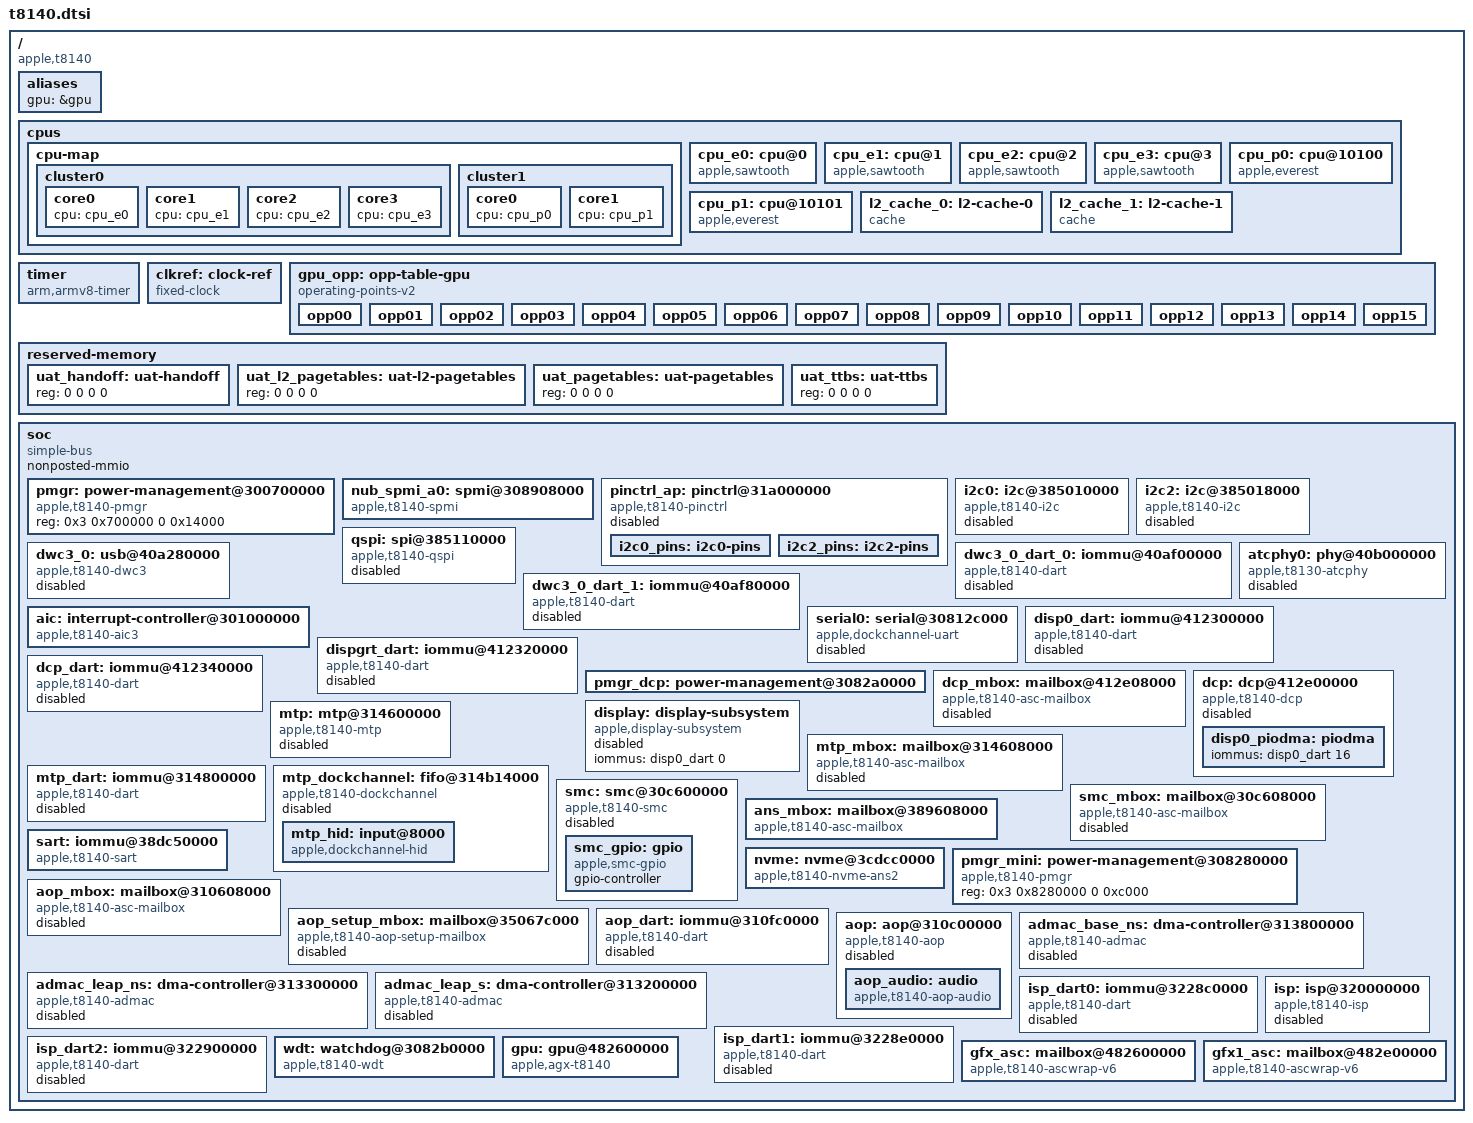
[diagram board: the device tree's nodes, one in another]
// SPDX-License-Identifier: GPL-2.0+ OR MIT
/*
 * Apple T8140 "A18 Pro" SoC
 *
 * Copyright The Asahi Linux Contributors
 */

#include <dt-bindings/interrupt-controller/apple-aic.h>
#include <dt-bindings/interrupt-controller/irq.h>
#include <dt-bindings/gpio/gpio.h>
#include <dt-bindings/pinctrl/apple.h>
#include <dt-bindings/phy/phy.h>
#include <dt-bindings/spmi/spmi.h>

/ {
	compatible = "apple,t8140", "apple,arm-platform";

	#address-cells = <2>;
	#size-cells = <2>;

	aliases {
		gpu = &gpu;
	};

	cpus {
		#address-cells = <2>;
		#size-cells = <0>;

		cpu-map {
			cluster0 {
				core0 {
					cpu = <&cpu_e0>;
				};
				core1 {
					cpu = <&cpu_e1>;
				};
				core2 {
					cpu = <&cpu_e2>;
				};
				core3 {
					cpu = <&cpu_e3>;
				};
			};

			cluster1 {
				core0 {
					cpu = <&cpu_p0>;
				};
				core1 {
					cpu = <&cpu_p1>;
				};
			};
		};

		cpu_e0: cpu@0 {
			compatible = "apple,sawtooth";
			device_type = "cpu";
			reg = <0x0 0x0>;
			enable-method = "spin-table";
			cpu-release-addr = <0 0>;
			next-level-cache = <&l2_cache_0>;
		};

		cpu_e1: cpu@1 {
			compatible = "apple,sawtooth";
			device_type = "cpu";
			reg = <0x0 0x1>;
			enable-method = "spin-table";
			cpu-release-addr = <0 0>;
			next-level-cache = <&l2_cache_0>;
		};


		cpu_e2: cpu@2 {
			compatible = "apple,sawtooth";
			device_type = "cpu";
			reg = <0x0 0x2>;
			enable-method = "spin-table";
			cpu-release-addr = <0 0>;
			next-level-cache = <&l2_cache_0>;
		};

		cpu_e3: cpu@3 {
			compatible = "apple,sawtooth";
			device_type = "cpu";
			reg = <0x0 0x3>;
			enable-method = "spin-table";
			cpu-release-addr = <0 0>;
			next-level-cache = <&l2_cache_0>;
		};

		cpu_p0: cpu@10100 {
			compatible = "apple,everest";
			device_type = "cpu";
			reg = <0x0 0x10100>;
			enable-method = "spin-table";
			cpu-release-addr = <0 0>;
			next-level-cache = <&l2_cache_1>;
		};

		cpu_p1: cpu@10101 {
			compatible = "apple,everest";
			device_type = "cpu";
			reg = <0x0 0x10101>;
			enable-method = "spin-table";
			cpu-release-addr = <0 0>;
			next-level-cache = <&l2_cache_1>;
		};

		l2_cache_0: l2-cache-0 {
			compatible = "cache";
			cache-level = <2>;
			cache-unified;
			cache-size = <0x400000>;
		};

		l2_cache_1: l2-cache-1 {
			compatible = "cache";
			cache-level = <2>;
			cache-unified;
			cache-size = <0x1000000>;
		};
	};

	timer {
		compatible = "arm,armv8-timer";
		interrupt-parent = <&aic>;
		interrupt-names = "phys", "virt", "hyp-phys", "hyp-virt";
		interrupts = <AIC_FIQ AIC_TMR_GUEST_PHYS IRQ_TYPE_LEVEL_HIGH>,
		             <AIC_FIQ AIC_TMR_GUEST_VIRT IRQ_TYPE_LEVEL_HIGH>,
		             <AIC_FIQ AIC_TMR_HV_PHYS IRQ_TYPE_LEVEL_HIGH>,
		             <AIC_FIQ AIC_TMR_HV_VIRT IRQ_TYPE_LEVEL_HIGH>;
	};

	clkref: clock-ref {
		compatible = "fixed-clock";
		#clock-cells = <0>;
		clock-frequency = <24000000>;
		clock-output-names = "clkref";
	};

	gpu_opp: opp-table-gpu {
		compatible = "operating-points-v2";

		/*
		 * NOTE: This ladder is the live J700 (Mac17,5) ADT
		 * perf-states table, kept in ADT order (the two interleaved
		 * rails make it non-monotonic); the bootloader rewrites it
		 * from each device's ADT.  opp-microwatt is deliberately
		 * absent: no G17P power model is grounded yet, and m1n1
		 * fails closed rather than inventing per-state power.
		 */
		opp00 {
			opp-hz = /bits/ 64 <0>;
			opp-microvolt = <125000>;
		};
		opp01 {
			opp-hz = /bits/ 64 <338000000>;
			opp-microvolt = <605000>;
		};
		opp02 {
			opp-hz = /bits/ 64 <492000000>;
			opp-microvolt = <630000>;
		};
		opp03 {
			opp-hz = /bits/ 64 <618000000>;
			opp-microvolt = <650000>;
		};
		opp04 {
			opp-hz = /bits/ 64 <796000000>;
			opp-microvolt = <695000>;
		};
		opp05 {
			opp-hz = /bits/ 64 <928000000>;
			opp-microvolt = <745000>;
		};
		opp06 {
			opp-hz = /bits/ 64 <952000000>;
			opp-microvolt = <800000>;
		};
		opp07 {
			opp-hz = /bits/ 64 <1056000000>;
			opp-microvolt = <800000>;
		};
		opp08 {
			opp-hz = /bits/ 64 <1053000000>;
			opp-microvolt = <845000>;
		};
		opp09 {
			opp-hz = /bits/ 64 <1170000000>;
			opp-microvolt = <845000>;
		};
		opp10 {
			opp-hz = /bits/ 64 <1152000000>;
			opp-microvolt = <885000>;
		};
		opp11 {
			opp-hz = /bits/ 64 <1278000000>;
			opp-microvolt = <885000>;
		};
		opp12 {
			opp-hz = /bits/ 64 <1204000000>;
			opp-microvolt = <905000>;
		};
		opp13 {
			opp-hz = /bits/ 64 <1338000000>;
			opp-microvolt = <905000>;
		};
		opp14 {
			opp-hz = /bits/ 64 <1326000000>;
			opp-microvolt = <975000>;
		};
		opp15 {
			opp-hz = /bits/ 64 <1470000000>;
			opp-microvolt = <975000>;
		};
	};

	reserved-memory {
		#address-cells = <2>;
		#size-cells = <2>;
		ranges;

		/*
		 * To be filled by the loader from the ADT sgx node:
		 * gpu-region -> uat-ttbs, gfx-shared-region -> uat-pagetables,
		 * gfx-shared-l2-region -> uat-l2-pagetables,
		 * gfx-handoff -> uat-handoff.
		 */
		uat_handoff: uat-handoff {
			reg = <0 0 0 0>;
		};

		uat_l2_pagetables: uat-l2-pagetables {
			reg = <0 0 0 0>;
		};

		uat_pagetables: uat-pagetables {
			reg = <0 0 0 0>;
		};

		uat_ttbs: uat-ttbs {
			reg = <0 0 0 0>;
		};
	};

	soc: soc {
		compatible = "simple-bus";
		#address-cells = <2>;
		#size-cells = <2>;

		nonposted-mmio;
		ranges;

		pmgr: power-management@300700000 {
			compatible = "apple,t8140-pmgr", "apple,t8103-pmgr", "syscon", "simple-mfd";
			#address-cells = <1>;
			#size-cells = <1>;
			reg = <0x3 0x700000 0 0x14000>;
			/* child nodes are added in t8140-pmgr.dtsi */
		};

		nub_spmi_a0: spmi@308908000 {
			compatible = "apple,t8140-spmi", "apple,t8103-spmi";
			reg = <0x3 0x08908000 0x0 0x100>;
			#address-cells = <2>;
			#size-cells = <0>;
			#interrupt-cells = <2>;
			interrupt-controller;
			interrupt-parent = <&aic>;
			interrupts = <AIC_IRQ 494 IRQ_TYPE_LEVEL_HIGH>;
			power-domains = <&ps_nub_spmi_a0>;
		};

		pinctrl_ap: pinctrl@31a000000 {
			compatible = "apple,t8140-pinctrl", "apple,t8103-pinctrl";
			reg = <0x3 0x1a000000 0x0 0x100000>;
			power-domains = <&ps_gpio>;

			gpio-controller;
			#gpio-cells = <2>;
			gpio-ranges = <&pinctrl_ap 0 0 216>;
			apple,npins = <216>;
			apple,no-regcache;

			/* Live J700 ADT /arm-io/gpio0 interrupts (7 groups). */
			interrupt-controller;
			#interrupt-cells = <2>;
			interrupt-parent = <&aic>;
			interrupts = <AIC_IRQ 263 IRQ_TYPE_LEVEL_HIGH>,
				     <AIC_IRQ 264 IRQ_TYPE_LEVEL_HIGH>,
				     <AIC_IRQ 265 IRQ_TYPE_LEVEL_HIGH>,
				     <AIC_IRQ 266 IRQ_TYPE_LEVEL_HIGH>,
				     <AIC_IRQ 267 IRQ_TYPE_LEVEL_HIGH>,
				     <AIC_IRQ 268 IRQ_TYPE_LEVEL_HIGH>,
				     <AIC_IRQ 269 IRQ_TYPE_LEVEL_HIGH>;
			/* ADT no-restore-gpio-pins entries: 50 and 134. */
			gpio-reserved-ranges = <50 1>, <134 1>;
			status = "disabled";

			i2c0_pins: i2c0-pins {
				pinmux = <APPLE_PINMUX(170, 1)>,
					 <APPLE_PINMUX(171, 1)>;
			};

			i2c2_pins: i2c2-pins {
				pinmux = <APPLE_PINMUX(165, 1)>,
					 <APPLE_PINMUX(164, 1)>;
			};
		};

		i2c0: i2c@385010000 {
			compatible = "apple,t8140-i2c", "apple,i2c";
			reg = <0x3 0x85010000 0x0 0x4000>;
			clocks = <&clkref>;
			interrupt-parent = <&aic>;
			interrupts = <AIC_IRQ 1108 IRQ_TYPE_LEVEL_HIGH>;
			pinctrl-0 = <&i2c0_pins>;
			pinctrl-names = "default";
			#address-cells = <1>;
			#size-cells = <0>;
			power-domains = <&ps_i2c0>;
			status = "disabled";
		};

		i2c2: i2c@385018000 {
			compatible = "apple,t8140-i2c", "apple,i2c";
			reg = <0x3 0x85018000 0x0 0x4000>;
			clocks = <&clkref>;
			interrupt-parent = <&aic>;
			interrupts = <AIC_IRQ 1110 IRQ_TYPE_LEVEL_HIGH>;
			pinctrl-0 = <&i2c2_pins>;
			pinctrl-names = "default";
			#address-cells = <1>;
			#size-cells = <0>;
			power-domains = <&ps_i2c2>;
			status = "disabled";
		};

		qspi: spi@385110000 {
			compatible = "apple,t8140-qspi";
			/* One aperture; the command block starts at offset 0x800. */
			reg = <0x3 0x85110000 0x0 0x4800>;
			interrupt-parent = <&aic>;
			interrupts = <AIC_IRQ 1106 IRQ_TYPE_LEVEL_HIGH>;
			clocks = <&clk_200m>;
			power-domains = <&ps_qspi>;
			#address-cells = <1>;
			#size-cells = <0>;
			status = "disabled";
		};

		dwc3_0: usb@40a280000 {
			compatible = "apple,t8140-dwc3", "apple,t8103-dwc3";
			reg = <0x4 0x0a280000 0x0 0xcd00>,
			      <0x4 0x0a28cd00 0x0 0x3200>;
			reg-names = "dwc3-core", "dwc3-apple";
			interrupt-parent = <&aic>;
			interrupts = <AIC_IRQ 1244 IRQ_TYPE_LEVEL_HIGH>;
			dr_mode = "otg";
			usb-role-switch;
			role-switch-default-mode = "host";
			iommus = <&dwc3_0_dart_0 0>, <&dwc3_0_dart_1 1>;
			power-domains = <&ps_atc0_usb>;
			resets = <&atcphy0>;
			phys = <&atcphy0 PHY_TYPE_USB2>, <&atcphy0 PHY_TYPE_USB3>;
			phy-names = "usb2-phy", "usb3-phy";
			hub-reset-gpios = <&pinctrl_ap 142 GPIO_ACTIVE_LOW>;
			status = "disabled";
		};

		dwc3_0_dart_0: iommu@40af00000 {
			compatible = "apple,t8140-dart", "apple,t8110-dart";
			reg = <0x4 0x0af00000 0x0 0xc000>;
			interrupt-parent = <&aic>;
			interrupts = <AIC_IRQ 1248 IRQ_TYPE_LEVEL_HIGH>;
			power-domains = <&ps_atc0_usb>;
			#iommu-cells = <1>;
			apple,dma-range = <0x100 0x00004000 0x0 0xffff0000>;
			status = "disabled";
		};

		dwc3_0_dart_1: iommu@40af80000 {
			compatible = "apple,t8140-dart", "apple,t8110-dart";
			reg = <0x4 0x0af80000 0x0 0xc000>;
			interrupt-parent = <&aic>;
			interrupts = <AIC_IRQ 1248 IRQ_TYPE_LEVEL_HIGH>;
			power-domains = <&ps_atc0_usb>;
			#iommu-cells = <1>;
			apple,dma-range = <0x100 0x00004000 0x0 0xffff0000>;
			status = "disabled";
		};

		atcphy0: phy@40b000000 {
			compatible = "apple,t8130-atcphy", "apple,t8122-atcphy";
			reg = <0x4 0x0b000000 0x0 0x4c000>,
			      <0x4 0x0b050000 0x0 0x4000>,
			      <0x4 0x08000000 0x0 0x8000>,
			      <0x4 0x0aa90000 0x0 0x4000>,
			      <0x4 0x0aa84000 0x0 0x4000>,
			      <0x4 0x0a300000 0x0 0x4000>;
			reg-names = "core", "lpdptx", "axi2af", "usb2phy",
				    "pipehandler", "usb2phy-reg";

			#phy-cells = <1>;
			#reset-cells = <0>;

			orientation-switch;
			mode-switch;
			power-domains = <&ps_atc0_usb>;
			apple,force-usb2-on;
			apple,force-usb2-host-preinit;
			status = "disabled";
		};

		aic: interrupt-controller@301000000 {
			compatible = "apple,t8140-aic3", "apple,t8122-aic3";
			#interrupt-cells = <3>;
			interrupt-controller;
			reg = <0x00000003 0x01000000 0x00000000 0x1cc000>,
			      <0x00000003 0x01040000 0x00000000 0x4000>;
			reg-names = "core", "event";
			power-domains = <&ps_aic>;
		};

		serial0: serial@30812c000 {
			compatible = "apple,dockchannel-uart";
			reg = <0x3 0x0812c000 0x0 0x4000>,
			      <0x3 0x08128000 0x0 0x4000>,
			      <0x3 0x0810c000 0x0 0x4000>;
			reg-names = "data", "config", "irq";
			interrupt-parent = <&aic>;
			interrupts = <AIC_IRQ 470 IRQ_TYPE_LEVEL_HIGH>;
			status = "disabled";
		};

		/*
		 * Live J700 ADT topology. These DARTs use a 1 TiB firmware-visible
		 * DVA prefix over a 36-bit hardware IOVA alias. DCP and display expose
		 * 29 SIDs, while the display GRT DART exposes 16.
		 * The SID-specific apertures used below are vm-size-23 for DCP and
		 * vm-size-0 for display, both 64 GiB. The verified consumers are DCP
		 * 23, DCP exclave 24, display 0, display PIODMA 16, scaler 3 and SCA
		 * 4, and display GRT 8.
		 *
		 * Keep all DARTs disabled: current firmware leaves DCP running and
		 * owns its endpoint map, shared memory and these translations. An
		 * unlocked apple-dart probe resets every stream, so enabling either
		 * node must wait for an explicit DCP lifecycle handoff.
		 */
		disp0_dart: iommu@412300000 {
			compatible = "apple,t8140-dart", "apple,t8110-dart";
			reg = <0x4 0x12300000 0x0 0xc000>;
			interrupt-parent = <&aic>;
			interrupts = <AIC_IRQ 698 IRQ_TYPE_LEVEL_HIGH>;
			power-domains = <&ps_disp_cpu>;
			#iommu-cells = <1>;
			apple,dma-range = <0x100 0x0 0x10 0x0>;
			status = "disabled";
		};

		dispgrt_dart: iommu@412320000 {
			compatible = "apple,t8140-dart", "apple,t8110-dart";
			reg = <0x4 0x12320000 0x0 0xc000>;
			interrupt-parent = <&aic>;
			interrupts = <AIC_IRQ 698 IRQ_TYPE_LEVEL_HIGH>;
			power-domains = <&ps_disp_cpu>;
			#iommu-cells = <1>;
			apple,dma-range = <0x100 0x0 0x10 0x0>;
			status = "disabled";
		};

		dcp_dart: iommu@412340000 {
			compatible = "apple,t8140-dart", "apple,t8110-dart";
			reg = <0x4 0x12340000 0x0 0xc000>;
			interrupt-parent = <&aic>;
			interrupts = <AIC_IRQ 698 IRQ_TYPE_LEVEL_HIGH>;
			power-domains = <&ps_disp_cpu>;
			#iommu-cells = <1>;
			apple,dma-range = <0x100 0x0 0x10 0x0>;
			status = "disabled";
		};

		/*
		 * DISP_INT uses PMC BWR agent 0 and boost agent 1. The H17P
		 * callback exports exactly eight bytes of BWR state and four bytes
		 * of clock-request state from these two windows.
		 */
		pmgr_dcp: power-management@3082a0000 {
			reg = <0x3 0x082a0000 0x0 0x8>,
			      <0x3 0x082e8000 0x0 0x4>;
			reg-names = "dcp-bw-scratch", "dcp-bw-doorbell";
			#apple,bw-scratch-cells = <3>;
			#apple,bw-doorbell-cells = <2>;
		};

		dcp_mbox: mailbox@412e08000 {
			compatible = "apple,t8140-asc-mailbox", "apple,asc-mailbox-v4";
			reg = <0x4 0x12e08000 0x0 0x4000>;
			interrupt-parent = <&aic>;
			interrupts = <AIC_IRQ 679 IRQ_TYPE_LEVEL_HIGH>,
				     <AIC_IRQ 680 IRQ_TYPE_LEVEL_HIGH>,
				     <AIC_IRQ 681 IRQ_TYPE_LEVEL_HIGH>,
				     <AIC_IRQ 682 IRQ_TYPE_LEVEL_HIGH>;
			interrupt-names = "send-empty", "send-not-empty",
					  "recv-empty", "recv-not-empty";
			power-domains = <&ps_disp_cpu>;
			resets = <&ps_disp_cpu>;
			#mbox-cells = <0>;
			status = "disabled";
		};

		dcp: dcp@412e00000 {
			compatible = "apple,t8140-dcp", "apple,dcp";
			mboxes = <&dcp_mbox>;
			mbox-names = "mbox";
			iommus = <&dcp_dart 23>;

			reg-names = "coproc", "disp-0", "disp-1", "disp-2",
				    "disp-3", "disp-4";
			reg = <0x4 0x12e00000 0x0 0x4000>,
			      <0x4 0x10000000 0x0 0xafc000>,
			      <0x4 0x12240000 0x0 0x10000>,
			      <0x4 0x123a8000 0x0 0x4000>,
			      <0x4 0x123ac000 0x0 0x4000>,
			      <0x4 0x12800000 0x0 0x800000>;
			apple,bw-scratch = <&pmgr_dcp 0 5 0>;
			apple,bw-doorbell = <&pmgr_dcp 1 6>;
			power-domains = <&ps_disp_cpu>;
			resets = <&ps_disp_cpu>;
			#address-cells = <2>;
			#size-cells = <2>;
			status = "disabled";

			disp0_piodma: piodma {
				iommus = <&disp0_dart 16>;
				phandle = <&disp0_piodma>;
			};
		};

		display: display-subsystem {
			compatible = "apple,display-subsystem";
			iommus = <&disp0_dart 0>;
			phandle = <&display>;
			status = "disabled";
		};

		mtp: mtp@314600000 {
			compatible = "apple,t8140-mtp",
				     "apple,t8140-rtk-helper-asc4",
				     "apple,mtp", "apple,rtk-helper-asc4";
			reg = <0x3 0x14600000 0x0 0x4000>,
			      <0x3 0x14050000 0x0 0x4000>;
			reg-names = "asc", "sram";
			mboxes = <&mtp_mbox>;
			iommus = <&mtp_dart 0>;
			#helper-cells = <0>;
			status = "disabled";
		};

		mtp_mbox: mailbox@314608000 {
			compatible = "apple,t8140-asc-mailbox",
				     "apple,asc-mailbox-v4";
			reg = <0x3 0x14608000 0x0 0x4000>;
			interrupt-parent = <&aic>;
			interrupts = <AIC_IRQ 1152 IRQ_TYPE_LEVEL_HIGH>,
				     <AIC_IRQ 1153 IRQ_TYPE_LEVEL_HIGH>,
				     <AIC_IRQ 1154 IRQ_TYPE_LEVEL_HIGH>,
				     <AIC_IRQ 1155 IRQ_TYPE_LEVEL_HIGH>;
			interrupt-names = "send-empty", "send-not-empty",
					  "recv-empty", "recv-not-empty";
			#mbox-cells = <0>;
			status = "disabled";
		};

		mtp_dart: iommu@314800000 {
			compatible = "apple,t8140-dart", "apple,t8110-dart";
			reg = <0x3 0x14800000 0x0 0xc000>;
			interrupt-parent = <&aic>;
			interrupts = <AIC_IRQ 1135 IRQ_TYPE_LEVEL_HIGH>;
			#iommu-cells = <1>;
			apple,dma-range = <0x100 0x00004000 0x0 0xffff0000>;
			status = "disabled";
		};

		mtp_dockchannel: fifo@314b14000 {
			compatible = "apple,t8140-dockchannel", "apple,dockchannel";
			reg = <0x3 0x14b14000 0x0 0x4000>;
			reg-names = "irq";
			interrupt-parent = <&aic>;
			interrupts = <AIC_IRQ 1137 IRQ_TYPE_LEVEL_HIGH>;

			ranges = <0x0 0x3 0x14b28000 0x20000>;
			nonposted-mmio;
			#address-cells = <1>;
			#size-cells = <1>;

			interrupt-controller;
			#interrupt-cells = <2>;
			status = "disabled";

			mtp_hid: input@8000 {
				compatible = "apple,dockchannel-hid";
				reg = <0x8000 0x4000>,
				      <0xc000 0x4000>,
				      <0x0000 0x4000>,
				      <0x4000 0x4000>;
				reg-names = "config", "data",
					    "rmt-config", "rmt-data";
				/* T8140 uses stream ID 0 for MTP, unlike older T8122. */
				iommus = <&mtp_dart 0>;
				interrupt-parent = <&mtp_dockchannel>;
				interrupts = <2 IRQ_TYPE_LEVEL_HIGH>,
					     <3 IRQ_TYPE_LEVEL_HIGH>;
				interrupt-names = "tx", "rx";
				apple,fifo-size = <0x800>;
				apple,helper-cpu = <&mtp>;
			};
		};

		/*
		 * Live J700 ADT /arm-io/smc.  The ASC and SRAM bases come from
		 * reg[0] and the iop-smc-nub region-base respectively.  The ADT
		 * mailbox interrupt tuple is ordered as paired pending/empty IRQs;
		 * normalize it to the Linux mailbox binding's ascending channel
		 * order, as is already done for the T8140 MTP mailbox above.
		 *
		 * Keep this disabled in the SoC description.  J700 must first prove
		 * inherited-session adoption without the ordinary macsmc notification
		 * and child-device writes before a board DTS enables it.
		 */
		smc_mbox: mailbox@30c608000 {
			compatible = "apple,t8140-asc-mailbox",
				     "apple,asc-mailbox-v4";
			reg = <0x3 0x0c608000 0x0 0x4000>;
			interrupt-parent = <&aic>;
			interrupts = <AIC_IRQ 581 IRQ_TYPE_LEVEL_HIGH>,
				     <AIC_IRQ 582 IRQ_TYPE_LEVEL_HIGH>,
				     <AIC_IRQ 583 IRQ_TYPE_LEVEL_HIGH>,
				     <AIC_IRQ 584 IRQ_TYPE_LEVEL_HIGH>;
			interrupt-names = "send-empty", "send-not-empty",
					  "recv-empty", "recv-not-empty";
			#mbox-cells = <0>;
			status = "disabled";
		};

		smc: smc@30c600000 {
			compatible = "apple,t8140-smc", "apple,t8103-smc",
				     "apple,smc";
			reg = <0x3 0x0c600000 0x0 0x4000>,
			      <0x3 0x0de00000 0x0 0x100000>;
			reg-names = "smc", "sram";
			mboxes = <&smc_mbox>;
			status = "disabled";

			smc_gpio: gpio {
				compatible = "apple,smc-gpio";
				gpio-controller;
				#gpio-cells = <2>;
			};
		};

		ans_mbox: mailbox@389608000 {
			compatible = "apple,t8140-asc-mailbox", "apple,asc-mailbox-v4";
			reg = <0x3 0x89608000 0x0 0x4000>;
			interrupt-parent = <&aic>;
			interrupts = <AIC_IRQ 1007 IRQ_TYPE_LEVEL_HIGH>,
				     <AIC_IRQ 1008 IRQ_TYPE_LEVEL_HIGH>,
				     <AIC_IRQ 1009 IRQ_TYPE_LEVEL_HIGH>,
				     <AIC_IRQ 1010 IRQ_TYPE_LEVEL_HIGH>;
			interrupt-names = "send-empty", "send-not-empty",
					  "recv-empty", "recv-not-empty";
			power-domains = <&ps_ans>;
			#mbox-cells = <0>;
		};

		sart: iommu@38dc50000 {
			compatible = "apple,t8140-sart", "apple,t6000-sart";
			reg = <0x3 0x8dc50000 0x0 0x10000>;
			power-domains = <&ps_ans>;
		};

		nvme: nvme@3cdcc0000 {
			compatible = "apple,t8140-nvme-ans2",
				     "apple,t8132-nvme-ans2";
			/*
			 * The ADT describes reg[9] as 0x10000, but the non-secure
			 * controller alias also contains the linear-SQ block at
			 * +0x24908..+0x24910.  Map through that block; otherwise the
			 * post-M4 submission doorbells land beyond Linux's ioremap.
			 */
			reg = <0x3 0xcdcc0000 0x0 0x30000>,
			      <0x3 0x89600000 0x0 0x4000>,
			      <0x3 0x8dcc0000 0x0 0x60000>;
			reg-names = "nvme", "ans", "nvmmu";
			interrupt-parent = <&aic>;
			interrupts = <AIC_IRQ 1039 IRQ_TYPE_LEVEL_HIGH>;
			mboxes = <&ans_mbox>;
			apple,sart = <&sart>;
			/*
			 * ps_apcie_phy_sw is otherwise referenced by nothing, so
			 * the PCIe PHY domain has no owner and powers down: ANS's
			 * link then falls to L1_IDLE and its first read asserts
			 * "apcie0[0]: Link timeout ... ltssm=0x14(L1_IDLE)".
			 * Holding it here keeps the link in L0; genpd powers its
			 * parents (apcie_sys_st and apcie_sys_gp) with it.
			 */
			power-domains = <&ps_ans>, <&ps_apcie_sys_st>,
					<&ps_apcie_phy_sw>;
			power-domain-names = "ans", "apcie0", "apcie_phy";
			resets = <&ps_ans>;
		};

		pmgr_mini: power-management@308280000 {
			compatible = "apple,t8140-pmgr", "apple,t8103-pmgr", "syscon", "simple-mfd";
			#address-cells = <1>;
			#size-cells = <1>;
			reg = <0x3 0x8280000 0 0xc000>;
			/* child nodes are added in t8140-pmgr.dtsi */
		};

		/*
		 * AOP (always-on processor).  Live J700 ADT /arm-io/aop
		 * (arm-io child + 0x210000000): reg[2] is the AOP MMIO window,
		 * reg[0] the ASCWrap v6 block whose mailbox sits at +0x8000.
		 * ADT interrupts [391, 390, 393, 392] = send-not-empty,
		 * send-empty, recv-not-empty, recv-empty.  The firmware
		 * (j700aop, RTKit 12) is iBoot-loaded and left stopped; Linux
		 * adopts it and never reloads it.
		 */
		aop_mbox: mailbox@310608000 {
			compatible = "apple,t8140-asc-mailbox", "apple,asc-mailbox-v4";
			reg = <0x3 0x10608000 0x0 0x4000>;
			interrupt-parent = <&aic>;
			interrupts = <AIC_IRQ 390 IRQ_TYPE_LEVEL_HIGH>,
				     <AIC_IRQ 391 IRQ_TYPE_LEVEL_HIGH>,
				     <AIC_IRQ 392 IRQ_TYPE_LEVEL_HIGH>,
				     <AIC_IRQ 393 IRQ_TYPE_LEVEL_HIGH>;
			interrupt-names = "send-empty", "send-not-empty",
					  "recv-empty", "recv-not-empty";
			#mbox-cells = <0>;
			status = "disabled";
		};

		/*
		 * The AOP "setup port": the second mailbox the J700 AOP firmware
		 * boots through (ADT /arm-io/aop-exclave-mailbox, absolute
		 * address 0x35067c000, IRQs [397, 394] = recv-not-empty,
		 * send-empty).  Register layout measured on hardware:
		 * A2I control +0x0 (FULL bit 16), I2A control +0x4 (EMPTY bit
		 * 17), send +0x180/+0x188, recv +0x1b0/+0x1b8.
		 */
		aop_setup_mbox: mailbox@35067c000 {
			compatible = "apple,t8140-aop-setup-mailbox";
			reg = <0x3 0x5067c000 0x0 0x4000>;
			interrupt-parent = <&aic>;
			interrupts = <AIC_IRQ 394 IRQ_TYPE_LEVEL_HIGH>,
				     <AIC_IRQ 397 IRQ_TYPE_LEVEL_HIGH>;
			interrupt-names = "send-empty", "recv-not-empty";
			/*
			 * Setup messages are exchanged through dart-aop stream 1,
			 * whose inherited root has its 64 GiB slot at the ADT
			 * vm-base-1 (0x20000000000) free for the host arena.
			 */
			iommus = <&aop_dart 1>;
			apple,dma-range = <0x200 0x0 0x10 0x0>;
			#mbox-cells = <0>;
			status = "disabled";
		};

		aop_dart: iommu@310fc0000 {
			compatible = "apple,t8140-dart", "apple,t8110-dart";
			reg = <0x3 0x10fc0000 0x0 0xc000>;
			#iommu-cells = <1>;
			interrupt-parent = <&aic>;
			interrupts = <AIC_IRQ 428 IRQ_TYPE_LEVEL_HIGH>;
			power-domains = <&ps_aop_base>;
			/*
			 * iBoot leaves this DART protected (PROTECT = 0x1e7): every
			 * stream root is inherited, so each consumer binds exactly
			 * one stream and the locked-DART path publishes into it.
			 */
			status = "disabled";
		};

		aop: aop@310c00000 {
			compatible = "apple,t8140-aop";
			reg = <0x3 0x10c00000 0x0 0x1e0000>,
			      <0x3 0x10600000 0x0 0x88000>;
			reg-names = "mmio", "asc";
			mboxes = <&aop_mbox>, <&aop_setup_mbox>;
			mbox-names = "mbox", "setup";
			iommus = <&aop_dart 0>;
			/*
			 * Stream 0's inherited root owns the 64 GiB slot at
			 * 0x10000000000 (the firmware's own mappings); the host's
			 * AFK buffers go into the next free slot of the ADT
			 * vm-base-0/vm-size-0 window.
			 */
			apple,dma-range = <0x110 0x0 0x10 0x0>;
			power-domains = <&ps_aop_cpu>;
			status = "disabled";

			/*
			 * Low-power microphone: the AOP firmware produces 16 kHz
			 * stereo S32 frames into a 512 KiB host ring bound through
			 * dart-aop stream 9 (mapper-admac-base-s, ADT vm-base-9 /
			 * vm-size-9); no ADMAC.
			 */
			aop_audio: audio {
				/* no apple,aop-audio fallback: the t8140 capture path
				 * (setup-port source ring, 16 kHz) is its own driver */
				compatible = "apple,t8140-aop-audio";
				iommus = <&aop_dart 9>;
				apple,dma-range = <0x100 0x40000000 0x0 0xffff0000>;
				/*
				 * Internal speaker: LEAP TX0 (admac-leap-ns channel 0,
				 * dart-aop stream 10) fed while the AOP spkr service is
				 * in pwrd; the LEAP power chain is brought up parent-
				 * first from tx0 and leap_mca.
				 */
				dmas = <&admac_leap_ns 0>, <&admac_base_ns 4>,
				       <&admac_base_ns 5>;
				dma-names = "spkr", "cout", "cin";
				/*
				 * 3.5 mm jack: base-ns TX2 (channel 4, dart-aop stream 8)
				 * into MCA1 while the AOP cout service is in pwrd, the
				 * headset microphone back from MCA1 on base-ns RX2
				 * (channel 5) under the cin service; the serializer
				 * domain audio_mca1_m is the AP's to power.
				 */
				power-domains = <&ps_audio_leap_tx0>, <&ps_audio_leap_mca>,
						<&ps_audio_mca1_m>;
				power-domain-names = "tx0", "mca", "mca1";
				#sound-dai-cells = <1>;
			};
		};

		/*
		 * The three "evolved" ADMAC instances of the audio fabric
		 * (live J700 ADT admac-base-ns / admac-leap-ns / admac-leap-s,
		 * compatible admac,t8140, admac-evolution = 1).  Register
		 * ranges are the ADT ones; the per-channel control/descriptor/
		 * report windows differ from t8103 and are described by the
		 * t8140 driver variant, not by older SoC offsets.  DMA streams:
		 * dart-aop mapper-admac-base-ns 8, mapper-admac-leap-ns 10,
		 * mapper-admac-leap-s 11 (exclave-gated under macOS).
		 */
		admac_base_ns: dma-controller@313800000 {
			compatible = "apple,t8140-admac", "apple,admac";
			reg = <0x3 0x13800000 0x0 0x34000>;
			dma-channels = <13>;
			interrupts-extended = <&aic AIC_IRQ 449 IRQ_TYPE_LEVEL_HIGH>,
					      <0>, <0>, <0>;
			#dma-cells = <1>;
			iommus = <&aop_dart 8>;
			/*
			 * Stream 8's inherited root has its slot 16 (IOVA 1 TiB..
			 * 1 TiB + 64 GiB) owned by the firmware, and the locked
			 * publish path never writes into a firmware-owned slot, so
			 * the AP's window sits in the free slot 17.
			 */
			apple,dma-range = <0x110 0x00000000 0x0 0x10000000>;
			power-domains = <&ps_audio_base_ns_a>;
			/* no resets: the AOP owns the audio fabric (see admac_leap_ns) */
			status = "disabled";
		};

		admac_leap_ns: dma-controller@313300000 {
			compatible = "apple,t8140-admac", "apple,admac";
			reg = <0x3 0x13300000 0x0 0x34000>;
			dma-channels = <9>;
			interrupts-extended = <&aic AIC_IRQ 452 IRQ_TYPE_LEVEL_HIGH>,
					      <0>, <0>, <0>;
			#dma-cells = <1>;
			iommus = <&aop_dart 10>;
			/* stream 10's inherited root is empty; use the generic window */
			apple,dma-range = <0x100 0x40000000 0x0 0xffff0000>;
			power-domains = <&ps_audio_leap_ns_a>;
			/*
			 * No resets: the AOP firmware owns the LEAP fabric and a
			 * second reset pulse (driver reload) wedged the block.
			 */
			status = "disabled";
		};

		admac_leap_s: dma-controller@313200000 {
			compatible = "apple,t8140-admac", "apple,admac";
			reg = <0x3 0x13200000 0x0 0x34000>;
			dma-channels = <9>;
			interrupts-extended = <&aic AIC_IRQ 451 IRQ_TYPE_LEVEL_HIGH>,
					      <0>, <0>, <0>;
			#dma-cells = <1>;
			iommus = <&aop_dart 11>;
			power-domains = <&ps_audio_leap_s_a>;
			resets = <&ps_audio_leap_s_a>;
			status = "disabled";
		};

		/*
		 * ISP (live J700 ADT /arm-io/isp, sensor-type 0x70, H17 "ISP17a"
		 * firmware, iBoot-loaded).  "coproc" is the ISP block, the IRQ
		 * block sits at +0x2920000 and the firmware GPIO words at
		 * +0x2921000 (measured in the m1n1 camera campaign).  "wdt" is
		 * the EIC mmio-wd-isp window: on T8140 the host must kick it at
		 * 30 Hz while streaming or every frame is the diagnostic fill.
		 * The three dart-isp instances share one SID0 page-table root.
		 */
		isp_dart0: iommu@3228c0000 {
			compatible = "apple,t8140-dart", "apple,t8110-dart";
			reg = <0x3 0x228c0000 0x0 0xc000>;
			#iommu-cells = <1>;
			interrupt-parent = <&aic>;
			interrupts = <AIC_IRQ 341 IRQ_TYPE_LEVEL_HIGH>;
			power-domains = <&ps_isp_sys>;
			/*
			 * 3-level tables (ias <= 36) as iBoot and the native host
			 * ran them: the ISP fetches at vm-base 0x10000000000 and the
			 * walk ignores the high bits; 32 GiB keeps the DAPF MMIO
			 * identity windows (up to 0x401660000) inside the aperture.
			 */
			apple,dma-range = <0x0 0x0 0x8 0x0>;
			/* ADT "remap": streams 1 2 6 7 10 11 are stream 0 */
			apple,remap-streams = <1 0>, <2 0>, <6 0>, <7 0>,
					      <10 0>, <11 0>;
			status = "disabled";
		};

		isp_dart1: iommu@3228e0000 {
			compatible = "apple,t8140-dart", "apple,t8110-dart";
			reg = <0x3 0x228e0000 0x0 0xc000>;
			#iommu-cells = <1>;
			interrupt-parent = <&aic>;
			interrupts = <AIC_IRQ 341 IRQ_TYPE_LEVEL_HIGH>;
			power-domains = <&ps_isp_sys>;
			/*
			 * 3-level tables (ias <= 36) as iBoot and the native host
			 * ran them: the ISP fetches at vm-base 0x10000000000 and the
			 * walk ignores the high bits; 32 GiB keeps the DAPF MMIO
			 * identity windows (up to 0x401660000) inside the aperture.
			 */
			apple,dma-range = <0x0 0x0 0x8 0x0>;
			/* ADT "remap": streams 1 2 6 7 10 11 are stream 0 */
			apple,remap-streams = <1 0>, <2 0>, <6 0>, <7 0>,
					      <10 0>, <11 0>;
			status = "disabled";
		};

		isp_dart2: iommu@322900000 {
			compatible = "apple,t8140-dart", "apple,t8110-dart";
			reg = <0x3 0x22900000 0x0 0xc000>;
			#iommu-cells = <1>;
			interrupt-parent = <&aic>;
			interrupts = <AIC_IRQ 341 IRQ_TYPE_LEVEL_HIGH>;
			power-domains = <&ps_isp_sys>;
			/*
			 * 3-level tables (ias <= 36) as iBoot and the native host
			 * ran them: the ISP fetches at vm-base 0x10000000000 and the
			 * walk ignores the high bits; 32 GiB keeps the DAPF MMIO
			 * identity windows (up to 0x401660000) inside the aperture.
			 */
			apple,dma-range = <0x0 0x0 0x8 0x0>;
			/* ADT "remap": streams 1 2 6 7 10 11 are stream 0 */
			apple,remap-streams = <1 0>, <2 0>, <6 0>, <7 0>,
					      <10 0>, <11 0>;
			status = "disabled";
		};

		/*
		 * ISP17a.  The ADT window is 0x320000000+0x3fe8000; "coproc"
		 * stops short of the secure route table at +0x1804000 (a read
		 * takes a sticky SError) and of the IRQ block (+0x2920000,
		 * "mbox": interrupt/enable words, doorbell/ack at +0x410) and
		 * the GPIO words (+0x2921000).  "wdt" is the EIC's mmio-wd-isp
		 * window the host kicks at 30 Hz while streaming.
		 */
		isp: isp@320000000 {
			compatible = "apple,t8140-isp", "apple,isp";
			iommus = <&isp_dart0 0>, <&isp_dart1 0>, <&isp_dart2 0>;
			reg-names = "coproc", "mbox", "gpio", "wdt";
			reg = <0x3 0x20000000 0x0 0x1801000>,
			      <0x3 0x22920000 0x0 0x1000>,
			      <0x3 0x22921000 0x0 0x100>,
			      <0x3 0x63b50000 0x0 0x8000>;
			interrupt-parent = <&aic>;
			/* ADT [323 324 325 326 336]; 323 carries the IPC mailbox */
			interrupts = <AIC_IRQ 323 IRQ_TYPE_LEVEL_HIGH>;
			power-domains = <&ps_isp_sys>, <&ps_isp_cpu>,
					<&ps_isp_cpu_core0>, <&ps_isp_cpu_core1>,
					<&ps_isp_fe>, <&ps_isp_dprx>, <&ps_isp_secure>,
					<&ps_isp_sts0>, <&ps_isp_sts1>, <&ps_isp_pearl>,
					<&ps_isp_be>, <&ps_isp_clr>, <&ps_isp_cvd>,
					<&ps_isp_cvm>;
			apple,dart-vm-size = <0x0 0xa0000000>;
			status = "disabled";
		};

		wdt: watchdog@3082b0000 {
			compatible = "apple,t8140-wdt", "apple,t8103-wdt";
			reg = <0x3 0x082b0000 0x0 0x4000>;
			clocks = <&clkref>;
			interrupt-parent = <&aic>;
			interrupts = <AIC_IRQ 481 IRQ_TYPE_LEVEL_HIGH>;
			/* The qualified J700 boot chain hands off through U-Boot. */
			u-boot,noautostart;
		};

		/*
		 * G17P GPU.  Addresses come from the live J700 ADT (arm-io
		 * child + 0x210000000): "asc" is the primary (GFX role)
		 * ASCWrap v6 window, "sgx" the GPU block MMIO.  The second
		 * compatible is the literal ADT identifier for this node.
		 * Unlike AGX2, T8140 has two independent GPU coprocessors;
		 * their mailboxes are the gfx_asc/gfx1_asc providers below,
		 * GFX first.
		 */
		gpu: gpu@482600000 {
			compatible = "apple,agx-t8140", "gpu,t8140";
			reg = <0x4 0x82600000 0x0 0x88000>,
			      <0x4 0x80000000 0x0 0x4000000>;
			reg-names = "asc", "sgx";
			mboxes = <&gfx_asc>, <&gfx1_asc>;
			power-domains = <&ps_gfx>;
			memory-region = <&uat_ttbs>, <&uat_pagetables>,
					<&uat_handoff>;
			memory-region-names = "ttbs", "pagetables", "handoff";
			operating-points-v2 = <&gpu_opp>;
		};

		gfx_asc: mailbox@482600000 {
			compatible = "apple,t8140-ascwrap-v6";
			reg = <0x4 0x82600000 0x0 0x88000>,
			      <0x4 0x82050000 0x0 0x8>;
			reg-names = "wrapper", "iop-vbar";
			interrupt-parent = <&aic>;
			interrupts = <AIC_IRQ 993 IRQ_TYPE_LEVEL_HIGH>,
				     <AIC_IRQ 996 IRQ_TYPE_LEVEL_HIGH>;
			interrupt-names = "send-empty", "recv-not-empty";
			apple,firmware-role = "GFX";
			power-domains = <&ps_gfx>;
			#mbox-cells = <0>;
		};

		gfx1_asc: mailbox@482e00000 {
			compatible = "apple,t8140-ascwrap-v6";
			reg = <0x4 0x82e00000 0x0 0x88000>,
			      <0x4 0x82850000 0x0 0x8>;
			reg-names = "wrapper", "iop-vbar";
			interrupt-parent = <&aic>;
			interrupts = <AIC_IRQ 997 IRQ_TYPE_LEVEL_HIGH>,
				     <AIC_IRQ 1000 IRQ_TYPE_LEVEL_HIGH>;
			interrupt-names = "send-empty", "recv-not-empty";
			apple,firmware-role = "GFX1";
			power-domains = <&ps_gfx>;
			#mbox-cells = <0>;
		};
	};
};

#include "t8140-pmgr.dtsi"
